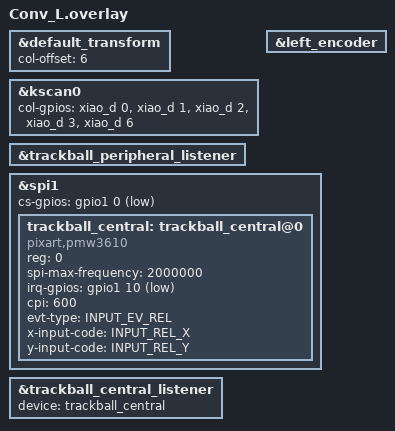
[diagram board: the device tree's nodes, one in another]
#include "Conv.dtsi"

&default_transform {
    col-offset = <6>;
};

&kscan0 {
        col-gpios
            = <&xiao_d 0 GPIO_ACTIVE_HIGH>
            , <&xiao_d 1 GPIO_ACTIVE_HIGH> 
            , <&xiao_d 2 GPIO_ACTIVE_HIGH> 
            , <&xiao_d 3 GPIO_ACTIVE_HIGH> 
            , <&xiao_d 6 GPIO_ACTIVE_HIGH>
            ;
};

&left_encoder {
    status = "okay";
};

&trackball_peripheral_listener {
    status = "okay";
};

#include <zephyr/dt-bindings/input/input-event-codes.h>
&spi1 {
    cs-gpios = <&gpio1 0 GPIO_ACTIVE_LOW>;

    trackball_central: trackball_central@0 {
        status = "okay";
        compatible = "pixart,pmw3610";
        reg = <0>;
        spi-max-frequency = <2000000>;
        irq-gpios = <&gpio1 10 (GPIO_ACTIVE_LOW | GPIO_PULL_UP)>;
        cpi = <600>;
        evt-type = <INPUT_EV_REL>;
        x-input-code = <INPUT_REL_X>;
        y-input-code = <INPUT_REL_Y>;
    };
};

// Overrides for the input listener node
    &trackball_central_listener {
    status = "okay";
    device = <&trackball_central>;
    };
